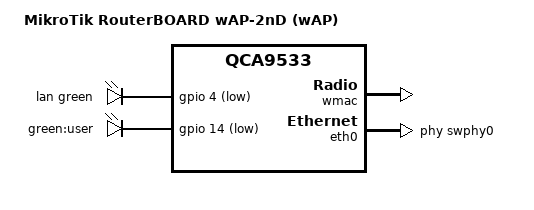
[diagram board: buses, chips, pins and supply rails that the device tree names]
// SPDX-License-Identifier: GPL-2.0-or-later OR MIT

#include <dt-bindings/leds/common.h>

#include "qca9533_mikrotik_routerboard-16m.dtsi"

/ {
	compatible = "mikrotik,routerboard-wap-2nd", "qca,qca9533";
	model = "MikroTik RouterBOARD wAP-2nD (wAP)";

	aliases {
		led-boot = &led_user;
		led-failsafe = &led_user;
		led-running = &led_user;
		led-upgrade = &led_user;
	};

	leds {
		compatible = "gpio-leds";
		pinctrl-names = "default";
		pinctrl-0 = <&led_lan_pin>;

		lan {
			function = LED_FUNCTION_LAN;
			color = <LED_COLOR_ID_GREEN>;
			gpios = <&gpio 4 GPIO_ACTIVE_LOW>;
		};

		led_user: user {
			label = "green:user";
			gpios = <&gpio 14 GPIO_ACTIVE_LOW>;
		};
	};
};

&wmac {
	status = "okay";

	qca,no-eeprom;

	led {
		led-sources = <11>;
		led-active-low;
	};
};

&eth0 {
	status = "okay";

	phy-handle = <&swphy0>;

	gmac-config {
		device = <&gmac>;
		switch-phy-swap = <1>;
	};
};

&eth1 {
	compatible = "syscon", "simple-mfd";
};

&pinmux {
	led_lan_pin: pinmux_led_lan_pin {
		pinctrl-single,bits = <0x4 0x0 0xff>;
	};
};
